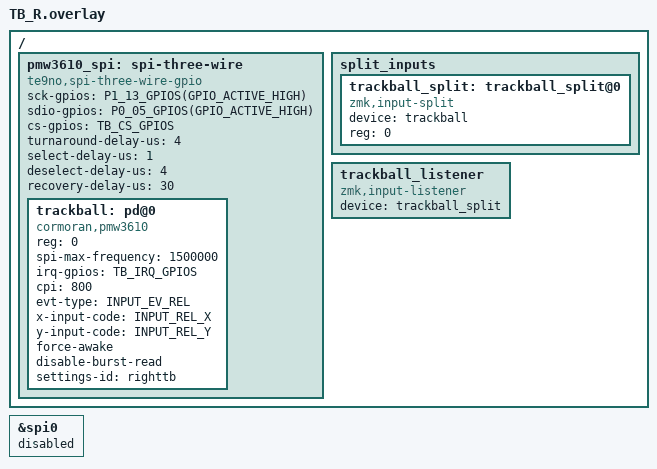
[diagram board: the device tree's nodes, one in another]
#include <input/processors.dtsi>
#include <dt-bindings/zmk/input_transform.h>
#include <zephyr/dt-bindings/input/input-event-codes.h>
#include <input/processors/runtime-input-processor.dtsi>

/ {
    pmw3610_spi: spi-three-wire {
        compatible = "te9no,spi-three-wire-gpio";
        status = "okay";
        #address-cells = <1>;
        #size-cells = <0>;

        sck-gpios = P1_13_GPIOS(GPIO_ACTIVE_HIGH);
        sdio-gpios = P0_05_GPIOS(GPIO_ACTIVE_HIGH);
        cs-gpios = TB_CS_GPIOS;

        turnaround-delay-us = <4>;
        select-delay-us = <1>;
        deselect-delay-us = <4>;
        recovery-delay-us = <30>;

        trackball: pd@0 {
            status = "okay";
            compatible = "cormoran,pmw3610";
            reg = <0>;
            spi-max-frequency = <1500000>;
            irq-gpios = TB_IRQ_GPIOS;
            cpi = <800>;
            evt-type = <INPUT_EV_REL>;
            x-input-code = <INPUT_REL_X>;
            y-input-code = <INPUT_REL_Y>;
            force-awake;
            disable-burst-read;
            settings-id = "righttb";
        };
    };

    split_inputs {
        #address-cells = <1>;
        #size-cells = <0>;

        trackball_split: trackball_split@0 {
            compatible = "zmk,input-split";
            status = "okay";
            device = <&trackball>;
            reg = <0>;
        };
    };

    trackball_listener: trackball_listener {
        compatible = "zmk,input-listener";
        status = "okay";
        device = <&trackball_split>;
    };
};

&spi0 {
    status = "disabled";
};
